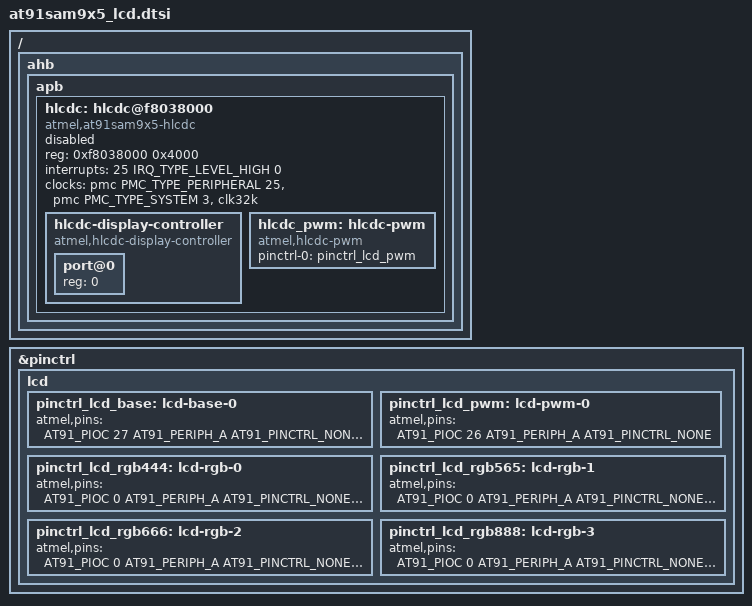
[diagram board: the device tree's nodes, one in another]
#include <dt-bindings/pinctrl/at91.h>
#include <dt-bindings/interrupt-controller/irq.h>
/ {
	ahb {
		apb {
			hlcdc: hlcdc@f8038000 {
				compatible = "atmel,at91sam9x5-hlcdc";
				reg = <0xf8038000 0x4000>;
				interrupts = <25 IRQ_TYPE_LEVEL_HIGH 0>;
				clocks = <&pmc PMC_TYPE_PERIPHERAL 25>, <&pmc PMC_TYPE_SYSTEM 3>, <&clk32k>;
				clock-names = "periph_clk","sys_clk", "slow_clk";
				status = "disabled";
				hlcdc-display-controller {
					compatible = "atmel,hlcdc-display-controller";
					#address-cells = <1>;
					#size-cells = <0>;
					port@0 {
						#address-cells = <1>;
						#size-cells = <0>;
						reg = <0>;
					};
				};
				hlcdc_pwm: hlcdc-pwm {
					compatible = "atmel,hlcdc-pwm";
					pinctrl-names = "default";
					pinctrl-0 = <&pinctrl_lcd_pwm>;
					#pwm-cells = <3>;
				};
			};
		};
	};
};
&pinctrl {
	lcd {
		pinctrl_lcd_base: lcd-base-0 {
			atmel,pins =
				<AT91_PIOC 27 AT91_PERIPH_A AT91_PINCTRL_NONE	 
				 AT91_PIOC 28 AT91_PERIPH_A AT91_PINCTRL_NONE	 
				 AT91_PIOC 24 AT91_PERIPH_A AT91_PINCTRL_NONE	 
				 AT91_PIOC 29 AT91_PERIPH_A AT91_PINCTRL_NONE	 
				 AT91_PIOC 30 AT91_PERIPH_A AT91_PINCTRL_NONE>;	 
		};
		pinctrl_lcd_pwm: lcd-pwm-0 {
			atmel,pins = <AT91_PIOC 26 AT91_PERIPH_A AT91_PINCTRL_NONE>;	 
		};
		pinctrl_lcd_rgb444: lcd-rgb-0 {
			atmel,pins =
				<AT91_PIOC 0 AT91_PERIPH_A AT91_PINCTRL_NONE	 
				 AT91_PIOC 1 AT91_PERIPH_A AT91_PINCTRL_NONE	 
				 AT91_PIOC 2 AT91_PERIPH_A AT91_PINCTRL_NONE	 
				 AT91_PIOC 3 AT91_PERIPH_A AT91_PINCTRL_NONE	 
				 AT91_PIOC 4 AT91_PERIPH_A AT91_PINCTRL_NONE	 
				 AT91_PIOC 5 AT91_PERIPH_A AT91_PINCTRL_NONE	 
				 AT91_PIOC 6 AT91_PERIPH_A AT91_PINCTRL_NONE	 
				 AT91_PIOC 7 AT91_PERIPH_A AT91_PINCTRL_NONE	 
				 AT91_PIOC 8 AT91_PERIPH_A AT91_PINCTRL_NONE	 
				 AT91_PIOC 9 AT91_PERIPH_A AT91_PINCTRL_NONE	 
				 AT91_PIOC 10 AT91_PERIPH_A AT91_PINCTRL_NONE	 
				 AT91_PIOC 11 AT91_PERIPH_A AT91_PINCTRL_NONE>;	 
		};
		pinctrl_lcd_rgb565: lcd-rgb-1 {
			atmel,pins =
				<AT91_PIOC 0 AT91_PERIPH_A AT91_PINCTRL_NONE	 
				 AT91_PIOC 1 AT91_PERIPH_A AT91_PINCTRL_NONE	 
				 AT91_PIOC 2 AT91_PERIPH_A AT91_PINCTRL_NONE	 
				 AT91_PIOC 3 AT91_PERIPH_A AT91_PINCTRL_NONE	 
				 AT91_PIOC 4 AT91_PERIPH_A AT91_PINCTRL_NONE	 
				 AT91_PIOC 5 AT91_PERIPH_A AT91_PINCTRL_NONE	 
				 AT91_PIOC 6 AT91_PERIPH_A AT91_PINCTRL_NONE	 
				 AT91_PIOC 7 AT91_PERIPH_A AT91_PINCTRL_NONE	 
				 AT91_PIOC 8 AT91_PERIPH_A AT91_PINCTRL_NONE	 
				 AT91_PIOC 9 AT91_PERIPH_A AT91_PINCTRL_NONE	 
				 AT91_PIOC 10 AT91_PERIPH_A AT91_PINCTRL_NONE	 
				 AT91_PIOC 11 AT91_PERIPH_A AT91_PINCTRL_NONE	 
				 AT91_PIOC 12 AT91_PERIPH_A AT91_PINCTRL_NONE	 
				 AT91_PIOC 13 AT91_PERIPH_A AT91_PINCTRL_NONE	 
				 AT91_PIOC 14 AT91_PERIPH_A AT91_PINCTRL_NONE	 
				 AT91_PIOC 15 AT91_PERIPH_A AT91_PINCTRL_NONE>;	 
		};
		pinctrl_lcd_rgb666: lcd-rgb-2 {
			atmel,pins =
				<AT91_PIOC 0 AT91_PERIPH_A AT91_PINCTRL_NONE	 
				 AT91_PIOC 1 AT91_PERIPH_A AT91_PINCTRL_NONE	 
				 AT91_PIOC 2 AT91_PERIPH_A AT91_PINCTRL_NONE	 
				 AT91_PIOC 3 AT91_PERIPH_A AT91_PINCTRL_NONE	 
				 AT91_PIOC 4 AT91_PERIPH_A AT91_PINCTRL_NONE	 
				 AT91_PIOC 5 AT91_PERIPH_A AT91_PINCTRL_NONE	 
				 AT91_PIOC 6 AT91_PERIPH_A AT91_PINCTRL_NONE	 
				 AT91_PIOC 7 AT91_PERIPH_A AT91_PINCTRL_NONE	 
				 AT91_PIOC 8 AT91_PERIPH_A AT91_PINCTRL_NONE	 
				 AT91_PIOC 9 AT91_PERIPH_A AT91_PINCTRL_NONE	 
				 AT91_PIOC 10 AT91_PERIPH_A AT91_PINCTRL_NONE	 
				 AT91_PIOC 11 AT91_PERIPH_A AT91_PINCTRL_NONE	 
				 AT91_PIOC 12 AT91_PERIPH_A AT91_PINCTRL_NONE	 
				 AT91_PIOC 13 AT91_PERIPH_A AT91_PINCTRL_NONE	 
				 AT91_PIOC 14 AT91_PERIPH_A AT91_PINCTRL_NONE	 
				 AT91_PIOC 15 AT91_PERIPH_A AT91_PINCTRL_NONE	 
				 AT91_PIOC 16 AT91_PERIPH_A AT91_PINCTRL_NONE	 
				 AT91_PIOC 17 AT91_PERIPH_A AT91_PINCTRL_NONE>;	 
		};
		pinctrl_lcd_rgb888: lcd-rgb-3 {
			atmel,pins =
				<AT91_PIOC 0 AT91_PERIPH_A AT91_PINCTRL_NONE	 
				 AT91_PIOC 1 AT91_PERIPH_A AT91_PINCTRL_NONE	 
				 AT91_PIOC 2 AT91_PERIPH_A AT91_PINCTRL_NONE	 
				 AT91_PIOC 3 AT91_PERIPH_A AT91_PINCTRL_NONE	 
				 AT91_PIOC 4 AT91_PERIPH_A AT91_PINCTRL_NONE	 
				 AT91_PIOC 5 AT91_PERIPH_A AT91_PINCTRL_NONE	 
				 AT91_PIOC 6 AT91_PERIPH_A AT91_PINCTRL_NONE	 
				 AT91_PIOC 7 AT91_PERIPH_A AT91_PINCTRL_NONE	 
				 AT91_PIOC 8 AT91_PERIPH_A AT91_PINCTRL_NONE	 
				 AT91_PIOC 9 AT91_PERIPH_A AT91_PINCTRL_NONE	 
				 AT91_PIOC 10 AT91_PERIPH_A AT91_PINCTRL_NONE	 
				 AT91_PIOC 11 AT91_PERIPH_A AT91_PINCTRL_NONE	 
				 AT91_PIOC 12 AT91_PERIPH_A AT91_PINCTRL_NONE	 
				 AT91_PIOC 13 AT91_PERIPH_A AT91_PINCTRL_NONE	 
				 AT91_PIOC 14 AT91_PERIPH_A AT91_PINCTRL_NONE	 
				 AT91_PIOC 15 AT91_PERIPH_A AT91_PINCTRL_NONE	 
				 AT91_PIOC 16 AT91_PERIPH_A AT91_PINCTRL_NONE	 
				 AT91_PIOC 17 AT91_PERIPH_A AT91_PINCTRL_NONE	 
				 AT91_PIOC 18 AT91_PERIPH_A AT91_PINCTRL_NONE	 
				 AT91_PIOC 19 AT91_PERIPH_A AT91_PINCTRL_NONE	 
				 AT91_PIOC 20 AT91_PERIPH_A AT91_PINCTRL_NONE	 
				 AT91_PIOC 21 AT91_PERIPH_A AT91_PINCTRL_NONE	 
				 AT91_PIOC 22 AT91_PERIPH_A AT91_PINCTRL_NONE	 
				 AT91_PIOC 23 AT91_PERIPH_A AT91_PINCTRL_NONE>;	 
		};
	};
};
